AUTOSAR XML (schema 00051)
package /Components
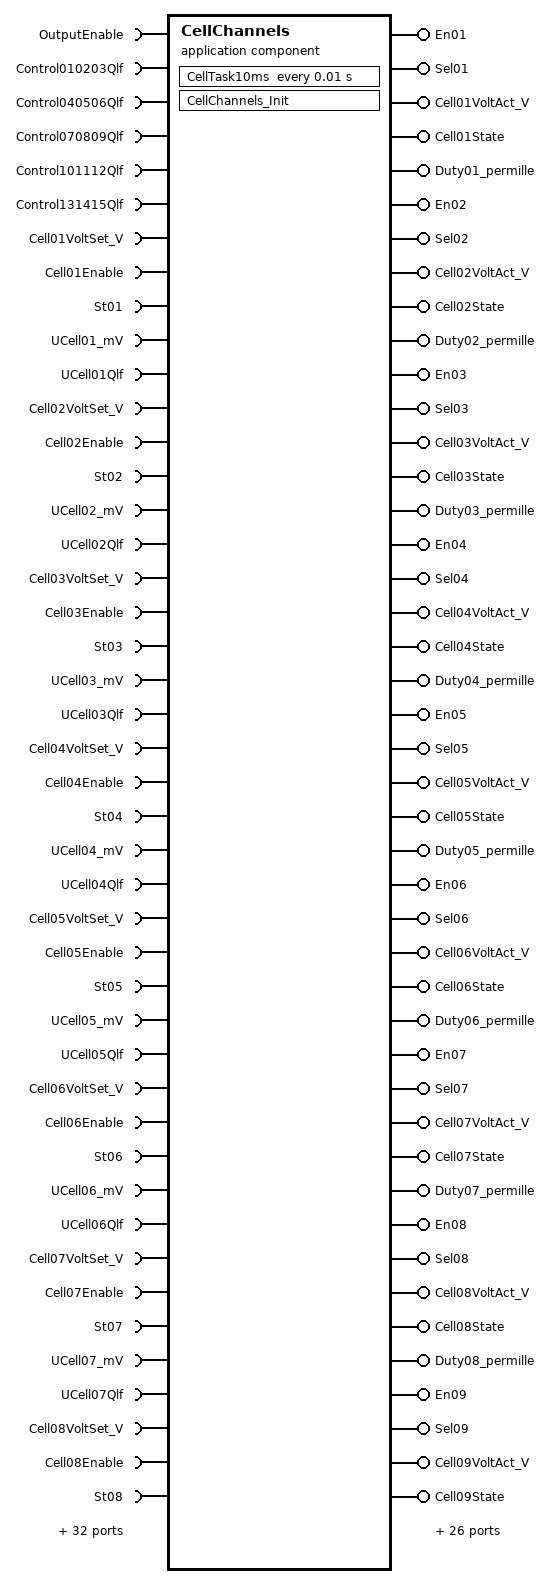
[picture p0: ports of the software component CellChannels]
  application sw component type CellChannels
    76 x require port:
      OutputEnable: nonqueued-receiver-com-spec{data-element=OutputEnable, init-value=0}, required-interface=OutputEnable
      Control010203Qlf: nonqueued-receiver-com-spec{data-element=Control010203Qlf, init-value=0}, required-interface=Control010203Qlf
      Control040506Qlf: nonqueued-receiver-com-spec{data-element=Control040506Qlf, init-value=0}, required-interface=Control040506Qlf
      Control070809Qlf: nonqueued-receiver-com-spec{data-element=Control070809Qlf, init-value=0}, required-interface=Control070809Qlf
      Control101112Qlf: nonqueued-receiver-com-spec{data-element=Control101112Qlf, init-value=0}, required-interface=Control101112Qlf
      Control131415Qlf: nonqueued-receiver-com-spec{data-element=Control131415Qlf, init-value=0}, required-interface=Control131415Qlf
      Cell01VoltSet_V: nonqueued-receiver-com-spec{data-element=Cell01VoltSet_V, init-value=0}, required-interface=Cell01VoltSet_V
      Cell01Enable: nonqueued-receiver-com-spec{data-element=Cell01Enable, init-value=0}, required-interface=Cell01Enable
      St01: nonqueued-receiver-com-spec{data-element=St01, init-value=0}, required-interface=St01
      UCell01_mV: nonqueued-receiver-com-spec{data-element=UCell01_mV, init-value=0}, required-interface=UCell01_mV
      UCell01Qlf: nonqueued-receiver-com-spec{data-element=UCell01Qlf, init-value=0}, required-interface=UCell01Qlf
      Cell02VoltSet_V: nonqueued-receiver-com-spec{data-element=Cell02VoltSet_V, init-value=0}, required-interface=Cell02VoltSet_V
      Cell02Enable: nonqueued-receiver-com-spec{data-element=Cell02Enable, init-value=0}, required-interface=Cell02Enable
      St02: nonqueued-receiver-com-spec{data-element=St02, init-value=0}, required-interface=St02
      UCell02_mV: nonqueued-receiver-com-spec{data-element=UCell02_mV, init-value=0}, required-interface=UCell02_mV
      UCell02Qlf: nonqueued-receiver-com-spec{data-element=UCell02Qlf, init-value=0}, required-interface=UCell02Qlf
      Cell03VoltSet_V: nonqueued-receiver-com-spec{data-element=Cell03VoltSet_V, init-value=0}, required-interface=Cell03VoltSet_V
      Cell03Enable: nonqueued-receiver-com-spec{data-element=Cell03Enable, init-value=0}, required-interface=Cell03Enable
      St03: nonqueued-receiver-com-spec{data-element=St03, init-value=0}, required-interface=St03
      UCell03_mV: nonqueued-receiver-com-spec{data-element=UCell03_mV, init-value=0}, required-interface=UCell03_mV
      UCell03Qlf: nonqueued-receiver-com-spec{data-element=UCell03Qlf, init-value=0}, required-interface=UCell03Qlf
      Cell04VoltSet_V: nonqueued-receiver-com-spec{data-element=Cell04VoltSet_V, init-value=0}, required-interface=Cell04VoltSet_V
      Cell04Enable: nonqueued-receiver-com-spec{data-element=Cell04Enable, init-value=0}, required-interface=Cell04Enable
      St04: nonqueued-receiver-com-spec{data-element=St04, init-value=0}, required-interface=St04
      UCell04_mV: nonqueued-receiver-com-spec{data-element=UCell04_mV, init-value=0}, required-interface=UCell04_mV
      UCell04Qlf: nonqueued-receiver-com-spec{data-element=UCell04Qlf, init-value=0}, required-interface=UCell04Qlf
      Cell05VoltSet_V: nonqueued-receiver-com-spec{data-element=Cell05VoltSet_V, init-value=0}, required-interface=Cell05VoltSet_V
      Cell05Enable: nonqueued-receiver-com-spec{data-element=Cell05Enable, init-value=0}, required-interface=Cell05Enable
      St05: nonqueued-receiver-com-spec{data-element=St05, init-value=0}, required-interface=St05
      UCell05_mV: nonqueued-receiver-com-spec{data-element=UCell05_mV, init-value=0}, required-interface=UCell05_mV
      UCell05Qlf: nonqueued-receiver-com-spec{data-element=UCell05Qlf, init-value=0}, required-interface=UCell05Qlf
      Cell06VoltSet_V: nonqueued-receiver-com-spec{data-element=Cell06VoltSet_V, init-value=0}, required-interface=Cell06VoltSet_V
      Cell06Enable: nonqueued-receiver-com-spec{data-element=Cell06Enable, init-value=0}, required-interface=Cell06Enable
      St06: nonqueued-receiver-com-spec{data-element=St06, init-value=0}, required-interface=St06
      UCell06_mV: nonqueued-receiver-com-spec{data-element=UCell06_mV, init-value=0}, required-interface=UCell06_mV
      UCell06Qlf: nonqueued-receiver-com-spec{data-element=UCell06Qlf, init-value=0}, required-interface=UCell06Qlf
      Cell07VoltSet_V: nonqueued-receiver-com-spec{data-element=Cell07VoltSet_V, init-value=0}, required-interface=Cell07VoltSet_V
      Cell07Enable: nonqueued-receiver-com-spec{data-element=Cell07Enable, init-value=0}, required-interface=Cell07Enable
      St07: nonqueued-receiver-com-spec{data-element=St07, init-value=0}, required-interface=St07
      UCell07_mV: nonqueued-receiver-com-spec{data-element=UCell07_mV, init-value=0}, required-interface=UCell07_mV
      UCell07Qlf: nonqueued-receiver-com-spec{data-element=UCell07Qlf, init-value=0}, required-interface=UCell07Qlf
      Cell08VoltSet_V: nonqueued-receiver-com-spec{data-element=Cell08VoltSet_V, init-value=0}, required-interface=Cell08VoltSet_V
      Cell08Enable: nonqueued-receiver-com-spec{data-element=Cell08Enable, init-value=0}, required-interface=Cell08Enable
      St08: nonqueued-receiver-com-spec{data-element=St08, init-value=0}, required-interface=St08
      UCell08_mV: nonqueued-receiver-com-spec{data-element=UCell08_mV, init-value=0}, required-interface=UCell08_mV
      UCell08Qlf: nonqueued-receiver-com-spec{data-element=UCell08Qlf, init-value=0}, required-interface=UCell08Qlf
      Cell09VoltSet_V: nonqueued-receiver-com-spec{data-element=Cell09VoltSet_V, init-value=0}, required-interface=Cell09VoltSet_V
      Cell09Enable: nonqueued-receiver-com-spec{data-element=Cell09Enable, init-value=0}, required-interface=Cell09Enable
      St09: nonqueued-receiver-com-spec{data-element=St09, init-value=0}, required-interface=St09
      UCell09_mV: nonqueued-receiver-com-spec{data-element=UCell09_mV, init-value=0}, required-interface=UCell09_mV
      UCell09Qlf: nonqueued-receiver-com-spec{data-element=UCell09Qlf, init-value=0}, required-interface=UCell09Qlf
      Cell10VoltSet_V: nonqueued-receiver-com-spec{data-element=Cell10VoltSet_V, init-value=0}, required-interface=Cell10VoltSet_V
      Cell10Enable: nonqueued-receiver-com-spec{data-element=Cell10Enable, init-value=0}, required-interface=Cell10Enable
      St10: nonqueued-receiver-com-spec{data-element=St10, init-value=0}, required-interface=St10
      UCell10_mV: nonqueued-receiver-com-spec{data-element=UCell10_mV, init-value=0}, required-interface=UCell10_mV
      UCell10Qlf: nonqueued-receiver-com-spec{data-element=UCell10Qlf, init-value=0}, required-interface=UCell10Qlf
      Cell11VoltSet_V: nonqueued-receiver-com-spec{data-element=Cell11VoltSet_V, init-value=0}, required-interface=Cell11VoltSet_V
      Cell11Enable: nonqueued-receiver-com-spec{data-element=Cell11Enable, init-value=0}, required-interface=Cell11Enable
      St11: nonqueued-receiver-com-spec{data-element=St11, init-value=0}, required-interface=St11
      UCell11_mV: nonqueued-receiver-com-spec{data-element=UCell11_mV, init-value=0}, required-interface=UCell11_mV
      UCell11Qlf: nonqueued-receiver-com-spec{data-element=UCell11Qlf, init-value=0}, required-interface=UCell11Qlf
      Cell12VoltSet_V: nonqueued-receiver-com-spec{data-element=Cell12VoltSet_V, init-value=0}, required-interface=Cell12VoltSet_V
      Cell12Enable: nonqueued-receiver-com-spec{data-element=Cell12Enable, init-value=0}, required-interface=Cell12Enable
      St12: nonqueued-receiver-com-spec{data-element=St12, init-value=0}, required-interface=St12
      UCell12_mV: nonqueued-receiver-com-spec{data-element=UCell12_mV, init-value=0}, required-interface=UCell12_mV
      UCell12Qlf: nonqueued-receiver-com-spec{data-element=UCell12Qlf, init-value=0}, required-interface=UCell12Qlf
      Cell13VoltSet_V: nonqueued-receiver-com-spec{data-element=Cell13VoltSet_V, init-value=0}, required-interface=Cell13VoltSet_V
      Cell13Enable: nonqueued-receiver-com-spec{data-element=Cell13Enable, init-value=0}, required-interface=Cell13Enable
      St13: nonqueued-receiver-com-spec{data-element=St13, init-value=0}, required-interface=St13
      UCell13_mV: nonqueued-receiver-com-spec{data-element=UCell13_mV, init-value=0}, required-interface=UCell13_mV
      UCell13Qlf: nonqueued-receiver-com-spec{data-element=UCell13Qlf, init-value=0}, required-interface=UCell13Qlf
      Cell14VoltSet_V: nonqueued-receiver-com-spec{data-element=Cell14VoltSet_V, init-value=0}, required-interface=Cell14VoltSet_V
      Cell14Enable: nonqueued-receiver-com-spec{data-element=Cell14Enable, init-value=0}, required-interface=Cell14Enable
      St14: nonqueued-receiver-com-spec{data-element=St14, init-value=0}, required-interface=St14
      UCell14_mV: nonqueued-receiver-com-spec{data-element=UCell14_mV, init-value=0}, required-interface=UCell14_mV
      UCell14Qlf: nonqueued-receiver-com-spec{data-element=UCell14Qlf, init-value=0}, required-interface=UCell14Qlf
    70 x provide port:
      En01: nonqueued-sender-com-spec{data-element=En01, init-value=0}, provided-interface=En01
      Sel01: nonqueued-sender-com-spec{data-element=Sel01, init-value=0}, provided-interface=Sel01
      Cell01VoltAct_V: nonqueued-sender-com-spec{data-element=Cell01VoltAct_V, init-value=0}, provided-interface=Cell01VoltAct_V
      Cell01State: nonqueued-sender-com-spec{data-element=Cell01State, init-value=0}, provided-interface=Cell01State
      Duty01_permille: nonqueued-sender-com-spec{data-element=Duty01_permille, init-value=0}, provided-interface=Duty01_permille
      En02: nonqueued-sender-com-spec{data-element=En02, init-value=0}, provided-interface=En02
      Sel02: nonqueued-sender-com-spec{data-element=Sel02, init-value=0}, provided-interface=Sel02
      Cell02VoltAct_V: nonqueued-sender-com-spec{data-element=Cell02VoltAct_V, init-value=0}, provided-interface=Cell02VoltAct_V
      Cell02State: nonqueued-sender-com-spec{data-element=Cell02State, init-value=0}, provided-interface=Cell02State
      Duty02_permille: nonqueued-sender-com-spec{data-element=Duty02_permille, init-value=0}, provided-interface=Duty02_permille
      En03: nonqueued-sender-com-spec{data-element=En03, init-value=0}, provided-interface=En03
      Sel03: nonqueued-sender-com-spec{data-element=Sel03, init-value=0}, provided-interface=Sel03
      Cell03VoltAct_V: nonqueued-sender-com-spec{data-element=Cell03VoltAct_V, init-value=0}, provided-interface=Cell03VoltAct_V
      Cell03State: nonqueued-sender-com-spec{data-element=Cell03State, init-value=0}, provided-interface=Cell03State
      Duty03_permille: nonqueued-sender-com-spec{data-element=Duty03_permille, init-value=0}, provided-interface=Duty03_permille
      En04: nonqueued-sender-com-spec{data-element=En04, init-value=0}, provided-interface=En04
      Sel04: nonqueued-sender-com-spec{data-element=Sel04, init-value=0}, provided-interface=Sel04
      Cell04VoltAct_V: nonqueued-sender-com-spec{data-element=Cell04VoltAct_V, init-value=0}, provided-interface=Cell04VoltAct_V
      Cell04State: nonqueued-sender-com-spec{data-element=Cell04State, init-value=0}, provided-interface=Cell04State
      Duty04_permille: nonqueued-sender-com-spec{data-element=Duty04_permille, init-value=0}, provided-interface=Duty04_permille
      En05: nonqueued-sender-com-spec{data-element=En05, init-value=0}, provided-interface=En05
      Sel05: nonqueued-sender-com-spec{data-element=Sel05, init-value=0}, provided-interface=Sel05
      Cell05VoltAct_V: nonqueued-sender-com-spec{data-element=Cell05VoltAct_V, init-value=0}, provided-interface=Cell05VoltAct_V
      Cell05State: nonqueued-sender-com-spec{data-element=Cell05State, init-value=0}, provided-interface=Cell05State
      Duty05_permille: nonqueued-sender-com-spec{data-element=Duty05_permille, init-value=0}, provided-interface=Duty05_permille
      En06: nonqueued-sender-com-spec{data-element=En06, init-value=0}, provided-interface=En06
      Sel06: nonqueued-sender-com-spec{data-element=Sel06, init-value=0}, provided-interface=Sel06
      Cell06VoltAct_V: nonqueued-sender-com-spec{data-element=Cell06VoltAct_V, init-value=0}, provided-interface=Cell06VoltAct_V
      Cell06State: nonqueued-sender-com-spec{data-element=Cell06State, init-value=0}, provided-interface=Cell06State
      Duty06_permille: nonqueued-sender-com-spec{data-element=Duty06_permille, init-value=0}, provided-interface=Duty06_permille
      En07: nonqueued-sender-com-spec{data-element=En07, init-value=0}, provided-interface=En07
      Sel07: nonqueued-sender-com-spec{data-element=Sel07, init-value=0}, provided-interface=Sel07
      Cell07VoltAct_V: nonqueued-sender-com-spec{data-element=Cell07VoltAct_V, init-value=0}, provided-interface=Cell07VoltAct_V
      Cell07State: nonqueued-sender-com-spec{data-element=Cell07State, init-value=0}, provided-interface=Cell07State
      Duty07_permille: nonqueued-sender-com-spec{data-element=Duty07_permille, init-value=0}, provided-interface=Duty07_permille
      En08: nonqueued-sender-com-spec{data-element=En08, init-value=0}, provided-interface=En08
      Sel08: nonqueued-sender-com-spec{data-element=Sel08, init-value=0}, provided-interface=Sel08
      Cell08VoltAct_V: nonqueued-sender-com-spec{data-element=Cell08VoltAct_V, init-value=0}, provided-interface=Cell08VoltAct_V
      Cell08State: nonqueued-sender-com-spec{data-element=Cell08State, init-value=0}, provided-interface=Cell08State
      Duty08_permille: nonqueued-sender-com-spec{data-element=Duty08_permille, init-value=0}, provided-interface=Duty08_permille
      En09: nonqueued-sender-com-spec{data-element=En09, init-value=0}, provided-interface=En09
      Sel09: nonqueued-sender-com-spec{data-element=Sel09, init-value=0}, provided-interface=Sel09
      Cell09VoltAct_V: nonqueued-sender-com-spec{data-element=Cell09VoltAct_V, init-value=0}, provided-interface=Cell09VoltAct_V
      Cell09State: nonqueued-sender-com-spec{data-element=Cell09State, init-value=0}, provided-interface=Cell09State
      Duty09_permille: nonqueued-sender-com-spec{data-element=Duty09_permille, init-value=0}, provided-interface=Duty09_permille
      En10: nonqueued-sender-com-spec{data-element=En10, init-value=0}, provided-interface=En10
      Sel10: nonqueued-sender-com-spec{data-element=Sel10, init-value=0}, provided-interface=Sel10
      Cell10VoltAct_V: nonqueued-sender-com-spec{data-element=Cell10VoltAct_V, init-value=0}, provided-interface=Cell10VoltAct_V
      Cell10State: nonqueued-sender-com-spec{data-element=Cell10State, init-value=0}, provided-interface=Cell10State
      Duty10_permille: nonqueued-sender-com-spec{data-element=Duty10_permille, init-value=0}, provided-interface=Duty10_permille
      En11: nonqueued-sender-com-spec{data-element=En11, init-value=0}, provided-interface=En11
      Sel11: nonqueued-sender-com-spec{data-element=Sel11, init-value=0}, provided-interface=Sel11
      Cell11VoltAct_V: nonqueued-sender-com-spec{data-element=Cell11VoltAct_V, init-value=0}, provided-interface=Cell11VoltAct_V
      Cell11State: nonqueued-sender-com-spec{data-element=Cell11State, init-value=0}, provided-interface=Cell11State
      Duty11_permille: nonqueued-sender-com-spec{data-element=Duty11_permille, init-value=0}, provided-interface=Duty11_permille
      En12: nonqueued-sender-com-spec{data-element=En12, init-value=0}, provided-interface=En12
      Sel12: nonqueued-sender-com-spec{data-element=Sel12, init-value=0}, provided-interface=Sel12
      Cell12VoltAct_V: nonqueued-sender-com-spec{data-element=Cell12VoltAct_V, init-value=0}, provided-interface=Cell12VoltAct_V
      Cell12State: nonqueued-sender-com-spec{data-element=Cell12State, init-value=0}, provided-interface=Cell12State
      Duty12_permille: nonqueued-sender-com-spec{data-element=Duty12_permille, init-value=0}, provided-interface=Duty12_permille
      En13: nonqueued-sender-com-spec{data-element=En13, init-value=0}, provided-interface=En13
      Sel13: nonqueued-sender-com-spec{data-element=Sel13, init-value=0}, provided-interface=Sel13
      Cell13VoltAct_V: nonqueued-sender-com-spec{data-element=Cell13VoltAct_V, init-value=0}, provided-interface=Cell13VoltAct_V
      Cell13State: nonqueued-sender-com-spec{data-element=Cell13State, init-value=0}, provided-interface=Cell13State
      Duty13_permille: nonqueued-sender-com-spec{data-element=Duty13_permille, init-value=0}, provided-interface=Duty13_permille
      En14: nonqueued-sender-com-spec{data-element=En14, init-value=0}, provided-interface=En14
      Sel14: nonqueued-sender-com-spec{data-element=Sel14, init-value=0}, provided-interface=Sel14
      Cell14VoltAct_V: nonqueued-sender-com-spec{data-element=Cell14VoltAct_V, init-value=0}, provided-interface=Cell14VoltAct_V
      Cell14State: nonqueued-sender-com-spec{data-element=Cell14State, init-value=0}, provided-interface=Cell14State
      Duty14_permille: nonqueued-sender-com-spec{data-element=Duty14_permille, init-value=0}, provided-interface=Duty14_permille
    behavior CellChannels_IB: handle-termination-and-restart=NO-SUPPORT
      timing event Event_CellTask10ms: start-on-event=CellTask10ms, period=0.01
      runnable CellChannels_Init
      runnable CellTask10ms
        data-send-points:
          70 x access:
            OUT_En01_En01: accessed-variable=En01.En01
            OUT_Sel01_Sel01: accessed-variable=Sel01.Sel01
            OUT_Cell01VoltAct_V_Cell01VoltAct_V: accessed-variable=Cell01VoltAct_V.Cell01VoltAct_V
            OUT_Cell01State_Cell01State: accessed-variable=Cell01State.Cell01State
            OUT_Duty01_permille_Duty01_permille: accessed-variable=Duty01_permille.Duty01_permille
            OUT_En02_En02: accessed-variable=En02.En02
            OUT_Sel02_Sel02: accessed-variable=Sel02.Sel02
            OUT_Cell02VoltAct_V_Cell02VoltAct_V: accessed-variable=Cell02VoltAct_V.Cell02VoltAct_V
            OUT_Cell02State_Cell02State: accessed-variable=Cell02State.Cell02State
            OUT_Duty02_permille_Duty02_permille: accessed-variable=Duty02_permille.Duty02_permille
            OUT_En03_En03: accessed-variable=En03.En03
            OUT_Sel03_Sel03: accessed-variable=Sel03.Sel03
            OUT_Cell03VoltAct_V_Cell03VoltAct_V: accessed-variable=Cell03VoltAct_V.Cell03VoltAct_V
            OUT_Cell03State_Cell03State: accessed-variable=Cell03State.Cell03State
            OUT_Duty03_permille_Duty03_permille: accessed-variable=Duty03_permille.Duty03_permille
            OUT_En04_En04: accessed-variable=En04.En04
            OUT_Sel04_Sel04: accessed-variable=Sel04.Sel04
            OUT_Cell04VoltAct_V_Cell04VoltAct_V: accessed-variable=Cell04VoltAct_V.Cell04VoltAct_V
            OUT_Cell04State_Cell04State: accessed-variable=Cell04State.Cell04State
            OUT_Duty04_permille_Duty04_permille: accessed-variable=Duty04_permille.Duty04_permille
            OUT_En05_En05: accessed-variable=En05.En05
            OUT_Sel05_Sel05: accessed-variable=Sel05.Sel05
            OUT_Cell05VoltAct_V_Cell05VoltAct_V: accessed-variable=Cell05VoltAct_V.Cell05VoltAct_V
            OUT_Cell05State_Cell05State: accessed-variable=Cell05State.Cell05State
            OUT_Duty05_permille_Duty05_permille: accessed-variable=Duty05_permille.Duty05_permille
            OUT_En06_En06: accessed-variable=En06.En06
            OUT_Sel06_Sel06: accessed-variable=Sel06.Sel06
            OUT_Cell06VoltAct_V_Cell06VoltAct_V: accessed-variable=Cell06VoltAct_V.Cell06VoltAct_V
            OUT_Cell06State_Cell06State: accessed-variable=Cell06State.Cell06State
            OUT_Duty06_permille_Duty06_permille: accessed-variable=Duty06_permille.Duty06_permille
            OUT_En07_En07: accessed-variable=En07.En07
            OUT_Sel07_Sel07: accessed-variable=Sel07.Sel07
            OUT_Cell07VoltAct_V_Cell07VoltAct_V: accessed-variable=Cell07VoltAct_V.Cell07VoltAct_V
            OUT_Cell07State_Cell07State: accessed-variable=Cell07State.Cell07State
            OUT_Duty07_permille_Duty07_permille: accessed-variable=Duty07_permille.Duty07_permille
            OUT_En08_En08: accessed-variable=En08.En08
            OUT_Sel08_Sel08: accessed-variable=Sel08.Sel08
            OUT_Cell08VoltAct_V_Cell08VoltAct_V: accessed-variable=Cell08VoltAct_V.Cell08VoltAct_V
            OUT_Cell08State_Cell08State: accessed-variable=Cell08State.Cell08State
            OUT_Duty08_permille_Duty08_permille: accessed-variable=Duty08_permille.Duty08_permille
            OUT_En09_En09: accessed-variable=En09.En09
            OUT_Sel09_Sel09: accessed-variable=Sel09.Sel09
            OUT_Cell09VoltAct_V_Cell09VoltAct_V: accessed-variable=Cell09VoltAct_V.Cell09VoltAct_V
            OUT_Cell09State_Cell09State: accessed-variable=Cell09State.Cell09State
            OUT_Duty09_permille_Duty09_permille: accessed-variable=Duty09_permille.Duty09_permille
            OUT_En10_En10: accessed-variable=En10.En10
            OUT_Sel10_Sel10: accessed-variable=Sel10.Sel10
            OUT_Cell10VoltAct_V_Cell10VoltAct_V: accessed-variable=Cell10VoltAct_V.Cell10VoltAct_V
            OUT_Cell10State_Cell10State: accessed-variable=Cell10State.Cell10State
            OUT_Duty10_permille_Duty10_permille: accessed-variable=Duty10_permille.Duty10_permille
            OUT_En11_En11: accessed-variable=En11.En11
            OUT_Sel11_Sel11: accessed-variable=Sel11.Sel11
            OUT_Cell11VoltAct_V_Cell11VoltAct_V: accessed-variable=Cell11VoltAct_V.Cell11VoltAct_V
            OUT_Cell11State_Cell11State: accessed-variable=Cell11State.Cell11State
            OUT_Duty11_permille_Duty11_permille: accessed-variable=Duty11_permille.Duty11_permille
            OUT_En12_En12: accessed-variable=En12.En12
            OUT_Sel12_Sel12: accessed-variable=Sel12.Sel12
            OUT_Cell12VoltAct_V_Cell12VoltAct_V: accessed-variable=Cell12VoltAct_V.Cell12VoltAct_V
            OUT_Cell12State_Cell12State: accessed-variable=Cell12State.Cell12State
            OUT_Duty12_permille_Duty12_permille: accessed-variable=Duty12_permille.Duty12_permille
            OUT_En13_En13: accessed-variable=En13.En13
            OUT_Sel13_Sel13: accessed-variable=Sel13.Sel13
            OUT_Cell13VoltAct_V_Cell13VoltAct_V: accessed-variable=Cell13VoltAct_V.Cell13VoltAct_V
            OUT_Cell13State_Cell13State: accessed-variable=Cell13State.Cell13State
            OUT_Duty13_permille_Duty13_permille: accessed-variable=Duty13_permille.Duty13_permille
            OUT_En14_En14: accessed-variable=En14.En14
            OUT_Sel14_Sel14: accessed-variable=Sel14.Sel14
            OUT_Cell14VoltAct_V_Cell14VoltAct_V: accessed-variable=Cell14VoltAct_V.Cell14VoltAct_V
            OUT_Cell14State_Cell14State: accessed-variable=Cell14State.Cell14State
            OUT_Duty14_permille_Duty14_permille: accessed-variable=Duty14_permille.Duty14_permille
